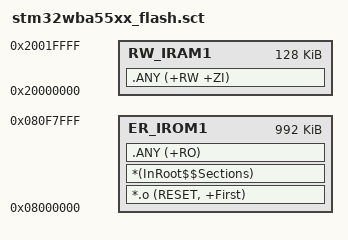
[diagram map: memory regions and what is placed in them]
; *************************************************************
; *** Scatter-Loading Description File generated by uVision ***
; *************************************************************

; Flash : 0x08000000 to 0x080F7FFF
; Persistence : 0x080F8000 to 0x080FFFFF
LR_IROM1 0x08000000 0x000F8000  
{    
  ; load address = execution address
  ER_IROM1      0x08000000 0x000F8000  
  {  
    *.o (RESET, +First)
    *(InRoot$$Sections)
    .ANY (+RO)
  }
  
  ; RW data RAM1 : 0x20000000 to 0x2001FFFF
  RW_IRAM1      0x20000000 0x00020000
  {  
   .ANY (+RW +ZI)
  }
}

